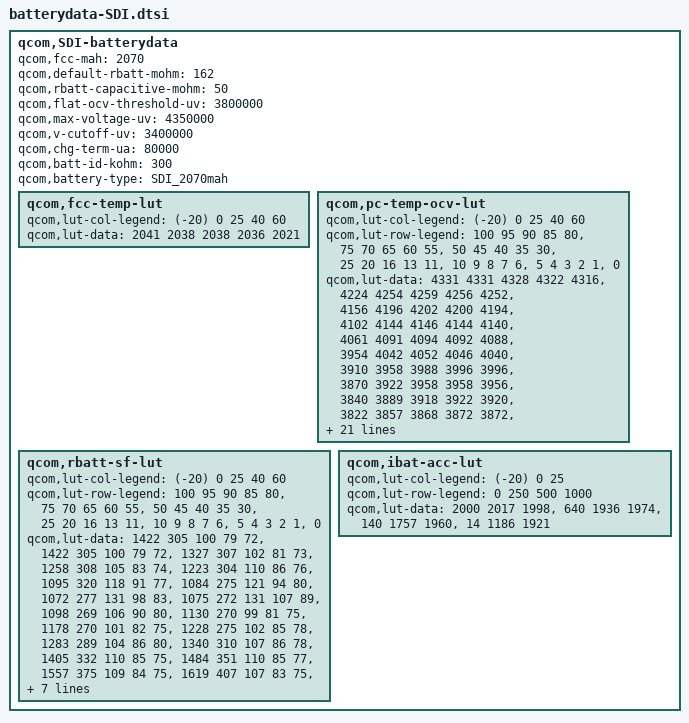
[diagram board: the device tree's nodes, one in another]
/* Copyright (c) 2013-2014  The Linux Foundation. All rights reserved.
 *
 * This program is free software; you can redistribute it and/or modify
 * it under the terms of the GNU General Public License version 2 and
 * only version 2 as published by the Free Software Foundation.
 *
 * This program is distributed in the hope that it will be useful,
 * but WITHOUT ANY WARRANTY; without even the implied warranty of
 * MERCHANTABILITY or FITNESS FOR A PARTICULAR PURPOSE.  See the
 * GNU General Public License for more details.
 */


qcom,SDI-batterydata {


	qcom,fcc-mah = <2070>;
	qcom,default-rbatt-mohm = <162>;
	qcom,rbatt-capacitive-mohm = <50>;
	qcom,flat-ocv-threshold-uv = <3800000>;
	qcom,max-voltage-uv = <4350000>;
	qcom,v-cutoff-uv = <3400000>;
	qcom,chg-term-ua = <80000>;
	qcom,batt-id-kohm = <300>;
	qcom,battery-type = "SDI_2070mah";

	qcom,fcc-temp-lut {
		qcom,lut-col-legend = <(-20) 0 25 40 60>;
		qcom,lut-data = <2041 2038 2038 2036 2021>;  
	};

	qcom,pc-temp-ocv-lut {
		qcom,lut-col-legend = <(-20) 0 25 40 60>;
		qcom,lut-row-legend = <100 95 90 85 80>,
				<75 70 65 60 55>,
				<50 45 40 35 30>,
				<25 20 16 13 11>,
				<10 9 8 7 6>,
				<5 4 3 2 1>,
				<0>;
		qcom,lut-data = <4331 4331 4328 4322 4316>,
				<4224 4254 4259 4256 4252>,
				<4156 4196 4202 4200 4194>,
				<4102 4144 4146 4144 4140>,
				<4061 4091 4094 4092 4088>,
				<3954 4042 4052 4046 4040>,
				<3910 3958 3988 3996 3996>,
				<3870 3922 3958 3958 3956>,
				<3840 3889 3918 3922 3920>,
				<3822 3857 3868 3872 3872>,
				<3806 3830 3836 3836 3836>,
				<3794 3808 3814 3814 3813>,
				<3781 3790 3796 3796 3795>,
				<3768 3780 3782 3781 3780>,
				<3755 3771 3772 3768 3762>,
				<3740 3760 3764 3755 3743>,
				<3724 3738 3746 3736 3722>,
				<3706 3720 3718 3708 3695>,
				<3688 3710 3698 3689 3675>,
				<3674 3704 3690 3682 3671>,
				<3664 3701 3689 3681 3670>,
				<3656 3698 3688 3680 3669>,
				<3644 3694 3687 3679 3668>,
				<3628 3690 3686 3678 3666>,
				<3608 3682 3681 3672 3661>,
				<3580 3664 3664 3650 3636>,
				<3542 3629 3622 3604 3590>,
				<3484 3570 3557 3538 3527>,
				<3384 3480 3466 3446 3441>,
				<3249 3336 3318 3284 3292>,
				<3079 3000 3030 3004 3000>;
	};

	qcom,rbatt-sf-lut {
		qcom,lut-col-legend = <(-20) 0 25 40 60>;
		qcom,lut-row-legend = <100 95 90 85 80>,
				<75 70 65 60 55>,
				<50 45 40 35 30>,
				<25 20 16 13 11>,
				<10 9 8 7 6>,
				<5 4 3 2 1>,
				<0>;
		qcom,lut-data = <1422 305 100 79 72>,
				<1422 305 100 79 72>,
				<1327 307 102 81 73>,
				<1258 308 105 83 74>,
				<1223 304 110 86 76>,
				<1095 320 118 91 77>,
				<1084 275 121 94 80>,
				<1072 277 131 98 83>,
				<1075 272 131 107 89>,
				<1098 269 106 90 80>,
				<1130 270 99 81 75>,
				<1178 270 101 82 75>,
				<1228 275 102 85 78>,
				<1283 289 104 86 80>,
				<1340 310 107 86 78>,
				<1405 332 110 85 75>,
				<1484 351 110 85 77>,
				<1557 375 109 84 75>,
				<1619 407 107 83 75>,
				<1675 436 108 85 76>,
				<1714 452 111 86 77>,
				<1635 454 113 88 78>,
				<1687 462 116 90 80>,
				<1873 488 121 93 83>,
				<2116 515 126 95 85>,
				<2431 539 126 93 79>,
				<2920 568 124 90 79>,
				<3758 614 131 96 84>,
				<7007 696 151 115 99>,
				<14015 1391 301 230 130>,
				<28030 2783 602 459 260>;
	};


	qcom,ibat-acc-lut {
		qcom,lut-col-legend = <(-20) 0 25>;
		qcom,lut-row-legend = <0 250 500 1000>;
		qcom,lut-data = <2000 2017 1998>,
				<640 1936 1974>,
				<140 1757 1960>,
				<14 1186 1921>;
	};


};
